# STM32U5Gx register map
File version: 1.0
CPU: CM33 r0p1, little endian, MPU, FPU, 4 interrupt priority bits
Registers are 32-bit, read-write, reset 0x0 unless marked. A register's access mark holds for its fields unless they carry their own. Offsets are from the block's base; [hi:lo] are bit positions.

## COMP — Comparator
Base 0x46005400
Same registers: SEC_COMP 0x56005400
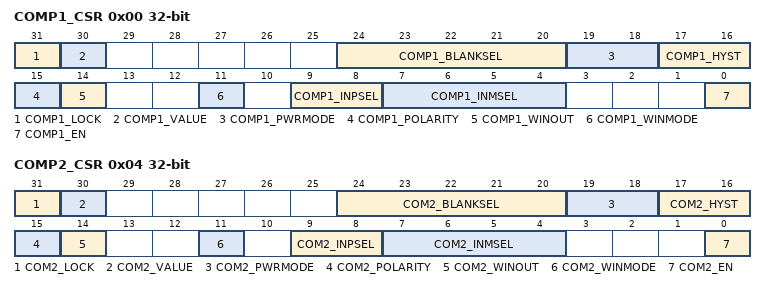
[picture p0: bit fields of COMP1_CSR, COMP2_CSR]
0x00 COMP1_CSR access per field — Comparator 1 control and status register
  [31] COMP1_LOCK rw — COMP1_CSR register lock bit
  [30] COMP1_VALUE ro — Comparator 1 output status bit
  [24:20] COMP1_BLANKSEL rw
  [19:18] COMP1_PWRMODE rw
  [17:16] COMP1_HYST rw — Comparator 1 hysteresis selection bits
  [15] COMP1_POLARITY rw — Comparator 1 polarity selection bit
  [14] COMP1_WINOUT rw
  [11] COMP1_WINMODE rw
  [9:8] COMP1_INPSEL rw — Comparator1 input plus selection bit
  [7:4] COMP1_INMSEL rw — Comparator 1 Input Minus connection configuration bit
  [0] COMP1_EN rw — Comparator 1 enable bit
0x04 COMP2_CSR access per field — Comparator 2 control and status register
  [31] COM2_LOCK rw — COMP2_CSR register lock bit
  [30] COM2_VALUE ro — Comparator 2 output status bit
  [24:20] COM2_BLANKSEL rw
  [19:18] COM2_PWRMODE rw
  [17:16] COM2_HYST rw — Comparator 2 hysteresis selection bits
  [15] COM2_POLARITY rw — Comparator 2 polarity selection bit
  [14] COM2_WINOUT rw
  [11] COM2_WINMODE rw
  [9:8] COM2_INPSEL rw — Comparator 2 input plus selection bit
  [7:4] COM2_INMSEL rw — Comparator 2 Input Minus connection configuration bit
  [0] COM2_EN rw — Comparator 2 enable bit

## CORDIC — CORDIC Co-processor
Base 0x40021000
Same registers: SEC_CORDIC 0x50021000
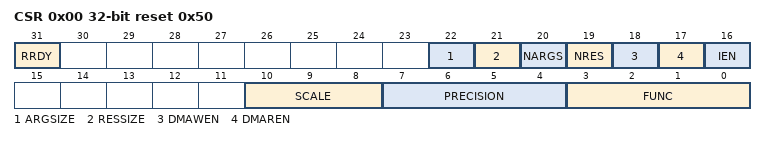
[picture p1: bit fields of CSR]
0x00 CSR access per field reset 0x50 — CORDIC Control Status register
  [31] RRDY ro — Result ready flag
  [22] ARGSIZE rw — Width of input data
  [21] RESSIZE rw — Width of output data
  [20] NARGS rw — Number of arguments expected by the CORDIC_WDATA register
  [19] NRES rw — Number of results in the CORDIC_RDATA register
  [18] DMAWEN rw — Enable DMA write channel
  [17] DMAREN rw — Enable DMA read channel
  [16] IEN rw — Enable interrupt
  [10:8] SCALE rw — Scaling factor
  [7:4] PRECISION rw — Precision required (number of iterations)
  [3:0] FUNC rw — Function
0x04 WDATA wo — FMAC Write Data register
  [31:0] ARG — Function input arguments
0x08 RDATA ro — FMAC Read Data register
  [31:0] RES — Function result

## CRC — Cyclic redundancy check calculation unit
Base 0x40023000
Same registers: SEC_CRC 0x50023000
0x00 DR reset 0xFFFFFFFF — Data register
  [31:0] DR — Data register bits
0x04 IDR — Independent data register
  [31:0] IDR — General-purpose 8-bit data register bits
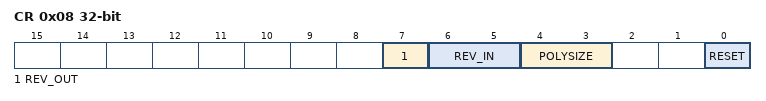
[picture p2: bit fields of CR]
0x08 CR — Control register
  [7] REV_OUT — Reverse output data
  [6:5] REV_IN — Reverse input data
  [4:3] POLYSIZE — Polynomial size
  [0] RESET — RESET bit
0x10 INIT reset 0xFFFFFFFF — Initial CRC value
  [31:0] CRC_INIT — Programmable initial CRC value
0x14 POL reset 0x4C11DB7 — polynomial
  [31:0] POL — Programmable polynomial

## CRS — Clock recovery system
Base 0x40006000
Same registers: SEC_CRS 0x50006000
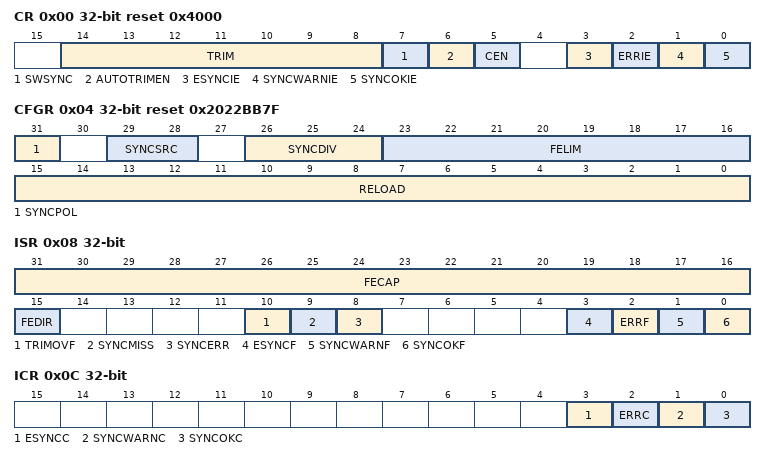
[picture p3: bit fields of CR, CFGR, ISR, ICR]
0x00 CR reset 0x4000 — control register
  [14:8] TRIM — HSI48 oscillator smooth trimming
  [7] SWSYNC — Generate software SYNC event
  [6] AUTOTRIMEN — Automatic trimming enable
  [5] CEN — Frequency error counter enable
  [3] ESYNCIE — Expected SYNC interrupt enable
  [2] ERRIE — Synchronization or trimming error interrupt enable
  [1] SYNCWARNIE — SYNC warning interrupt enable
  [0] SYNCOKIE — SYNC event OK interrupt enable
0x04 CFGR reset 0x2022BB7F — configuration register
  [31] SYNCPOL — SYNC polarity selection
  [29:28] SYNCSRC — SYNC signal source selection
  [26:24] SYNCDIV — SYNC divider
  [23:16] FELIM — Frequency error limit
  [15:0] RELOAD — Counter reload value
0x08 ISR ro — interrupt and status register
  [31:16] FECAP — Frequency error capture
  [15] FEDIR — Frequency error direction
  [10] TRIMOVF — Trimming overflow or underflow
  [9] SYNCMISS — SYNC missed
  [8] SYNCERR — SYNC error
  [3] ESYNCF — Expected SYNC flag
  [2] ERRF — Error flag
  [1] SYNCWARNF — SYNC warning flag
  [0] SYNCOKF — SYNC event OK flag
0x0C ICR — interrupt flag clear register
  [3] ESYNCC — Expected SYNC clear flag
  [2] ERRC — Error clear flag
  [1] SYNCWARNC — SYNC warning clear flag
  [0] SYNCOKC — SYNC event OK clear flag
